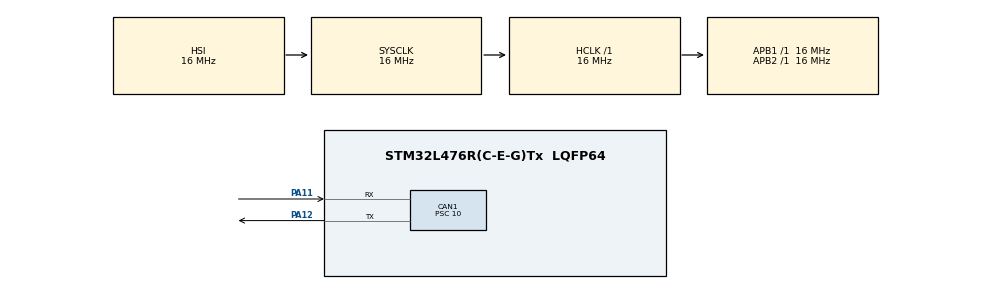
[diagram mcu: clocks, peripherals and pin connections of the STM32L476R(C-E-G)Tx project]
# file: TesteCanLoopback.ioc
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CAN1.BS1=CAN_BS1_13TQ
CAN1.BS2=CAN_BS2_2TQ
CAN1.CalculateBaudRate=100000
CAN1.CalculateTimeBit=10000
CAN1.CalculateTimeQuantum=625.0
CAN1.Mode=CAN_MODE_LOOPBACK
CAN1.Prescaler=10
Mcu.Family=STM32L4
Mcu.Name=STM32L476R(C-E-G)Tx
Mcu.Package=LQFP64
NVIC.CAN1_RX0_IRQn=true\:0\:0\:false\:false\:true\:true\:true\:true
NVIC.PriorityGroup=NVIC_PRIORITYGROUP_4
PA11.Mode=CAN_Activate
PA11.Signal=CAN1_RX
PA12.Mode=CAN_Activate
PA12.Signal=CAN1_TX
ProjectManager.HeapSize=0x200
ProjectManager.StackSize=0x400
ProjectManager.TargetToolchain=STM32CubeIDE
RCC.AHBFreq_Value=16000000
RCC.APB1Freq_Value=16000000
RCC.APB1TimFreq_Value=16000000
RCC.APB2Freq_Value=16000000
RCC.APB2TimFreq_Value=16000000
RCC.CortexFreq_Value=16000000
RCC.HCLKFreq_Value=16000000
RCC.HSE_VALUE=8000000
RCC.HSI_VALUE=16000000
RCC.LSE_VALUE=32768
RCC.MSI_VALUE=4000000
RCC.SYSCLKFreq_VALUE=16000000
RCC.SYSCLKSource=RCC_SYSCLKSOURCE_HSI
RCC.VCOOutputFreq_Value=32000000
board=custom

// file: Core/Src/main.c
/* USER CODE BEGIN Header */
/**
  ******************************************************************************
  * @file           : main.c
  * @brief          : Main program body
  ******************************************************************************
  * @attention
  *
  * Copyright (c) 2022 STMicroelectronics.
  * All rights reserved.
  *
  * This software is licensed under terms that can be found in the LICENSE file
  * in the root directory of this software component.
  * If no LICENSE file comes with this software, it is provided AS-IS.
  *
  ******************************************************************************
  */
/* USER CODE END Header */
#include "main.h"

/* USER CODE BEGIN Includes */

CAN_TxHeaderTypeDef TxHeader;
CAN_RxHeaderTypeDef RxHeader;

uint8_t TxData[8];
uint8_t RxData[8];
uint32_t TxMailbox;

uint8_t intg;

/* USER CODE END Includes */

 CAN_HandleTypeDef hcan1;

void SystemClock_Config(void);
static void MX_GPIO_Init(void);
static void MX_CAN1_Init(void);

/* USER CODE BEGIN 0 */

//Interrupção de Recepção CAN1...
void HAL_CAN_RxFifo0MsgPendingCallback(CAN_HandleTypeDef *hcan)
{

	HAL_CAN_GetRxMessage(&hcan1, CAN_RX_FIFO0, &RxHeader, RxData);
	intg++;

}

/* USER CODE END 0 */

int main(void)
{

  /* MCU Configuration--------------------------------------------------------*/

  /* Reset of all peripherals, Initializes the Flash interface and the Systick. */
  HAL_Init();

  /* Configure the system clock */
  SystemClock_Config();

  /* Initialize all configured peripherals */
  MX_GPIO_Init();
  MX_CAN1_Init();
  /* USER CODE BEGIN 2 */

  //Inicializa o CAN...
  HAL_CAN_Start(&hcan1);

  //Ativa a notificação para acessar a interrupção...
  HAL_CAN_ActivateNotification(&hcan1, CAN_IT_RX_FIFO0_MSG_PENDING);

  /* USER CODE END 2 */

  /* Infinite loop */
  while (1)
  {

    /* USER CODE BEGIN 3 */

	  //Informações a serem enviadas 1...
	   TxHeader.StdId = 0x11;
	   TxHeader.RTR = CAN_RTR_DATA;
	   TxHeader.IDE = CAN_ID_STD;
	   TxHeader.DLC = 2;
	   TxHeader.TransmitGlobalTime = DISABLE;
	   TxData[0] = 0x03;
	   TxData[1] = 0x04;

	   //Requisitar Transmissão...
	   HAL_CAN_AddTxMessage(&hcan1, &TxHeader, TxData, &TxMailbox);

	   HAL_Delay(2500);

	   //Informações a serem enviadas 2...
	   TxHeader.StdId = 0x12;
	   TxHeader.RTR = CAN_RTR_DATA;
	   TxHeader.IDE = CAN_ID_STD;
	   TxHeader.DLC = 3;
	   TxHeader.TransmitGlobalTime = DISABLE;
	   TxData[0] = 0x08;
	   TxData[1] = 0x09;
	   TxData[2] = 0x0A;

	   //Requisitar Transmissão...
	   HAL_CAN_AddTxMessage(&hcan1, &TxHeader, TxData, &TxMailbox);

	   HAL_Delay(2500);
  }
  /* USER CODE END 3 */
}

void SystemClock_Config(void)
{
  RCC_OscInitTypeDef RCC_OscInitStruct = {0};
  RCC_ClkInitTypeDef RCC_ClkInitStruct = {0};

  /** Configure the main internal regulator output voltage
  */
  if (HAL_PWREx_ControlVoltageScaling(PWR_REGULATOR_VOLTAGE_SCALE1) != HAL_OK)
  {
    Error_Handler();
  }

  /** Initializes the RCC Oscillators according to the specified parameters
  * in the RCC_OscInitTypeDef structure.
  */
  RCC_OscInitStruct.OscillatorType = RCC_OSCILLATORTYPE_HSI;
  RCC_OscInitStruct.HSIState = RCC_HSI_ON;
  RCC_OscInitStruct.HSICalibrationValue = RCC_HSICALIBRATION_DEFAULT;
  RCC_OscInitStruct.PLL.PLLState = RCC_PLL_NONE;
  if (HAL_RCC_OscConfig(&RCC_OscInitStruct) != HAL_OK)
  {
    Error_Handler();
  }

  /** Initializes the CPU, AHB and APB buses clocks
  */
  RCC_ClkInitStruct.ClockType = RCC_CLOCKTYPE_HCLK|RCC_CLOCKTYPE_SYSCLK
                              |RCC_CLOCKTYPE_PCLK1|RCC_CLOCKTYPE_PCLK2;
  RCC_ClkInitStruct.SYSCLKSource = RCC_SYSCLKSOURCE_HSI;
  RCC_ClkInitStruct.AHBCLKDivider = RCC_SYSCLK_DIV1;
  RCC_ClkInitStruct.APB1CLKDivider = RCC_HCLK_DIV1;
  RCC_ClkInitStruct.APB2CLKDivider = RCC_HCLK_DIV1;

  if (HAL_RCC_ClockConfig(&RCC_ClkInitStruct, FLASH_LATENCY_0) != HAL_OK)
  {
    Error_Handler();
  }
}

static void MX_CAN1_Init(void)
{

  hcan1.Instance = CAN1;
  hcan1.Init.Prescaler = 10;
  hcan1.Init.Mode = CAN_MODE_LOOPBACK;
  hcan1.Init.SyncJumpWidth = CAN_SJW_1TQ;
  hcan1.Init.TimeSeg1 = CAN_BS1_13TQ;
  hcan1.Init.TimeSeg2 = CAN_BS2_2TQ;
  hcan1.Init.TimeTriggeredMode = DISABLE;
  hcan1.Init.AutoBusOff = DISABLE;
  hcan1.Init.AutoWakeUp = DISABLE;
  hcan1.Init.AutoRetransmission = ENABLE;
  hcan1.Init.ReceiveFifoLocked = DISABLE;
  hcan1.Init.TransmitFifoPriority = DISABLE;

  if (HAL_CAN_Init(&hcan1) != HAL_OK)
  {
    Error_Handler();
  }

  /* USER CODE BEGIN CAN1_Init 2 */

  CAN_FilterTypeDef  sFilterConfig;

  /*##-2- Configure the CAN Filter ###########################################*/

  sFilterConfig.FilterBank = 0;
  sFilterConfig.FilterMode = CAN_FILTERMODE_IDMASK;
  sFilterConfig.FilterScale = CAN_FILTERSCALE_32BIT;
  sFilterConfig.FilterIdHigh = 0x0000;
  sFilterConfig.FilterIdLow = 0x0000;
  sFilterConfig.FilterMaskIdHigh = 0x0000;
  sFilterConfig.FilterMaskIdLow = 0x0000;
  sFilterConfig.FilterFIFOAssignment = CAN_RX_FIFO0;
  sFilterConfig.FilterActivation = ENABLE;
  sFilterConfig.SlaveStartFilterBank = 14;

  if(HAL_CAN_ConfigFilter(&hcan1, &sFilterConfig) != HAL_OK)
    {
      /* Filter configuration Error */
      Error_Handler();
    }

  /* USER CODE END CAN1_Init 2 */

}

static void MX_GPIO_Init(void)
{

  /* GPIO Ports Clock Enable */
  __HAL_RCC_GPIOA_CLK_ENABLE();

}

void Error_Handler(void)
{
  __disable_irq();
  while (1)
  {
  }
}
